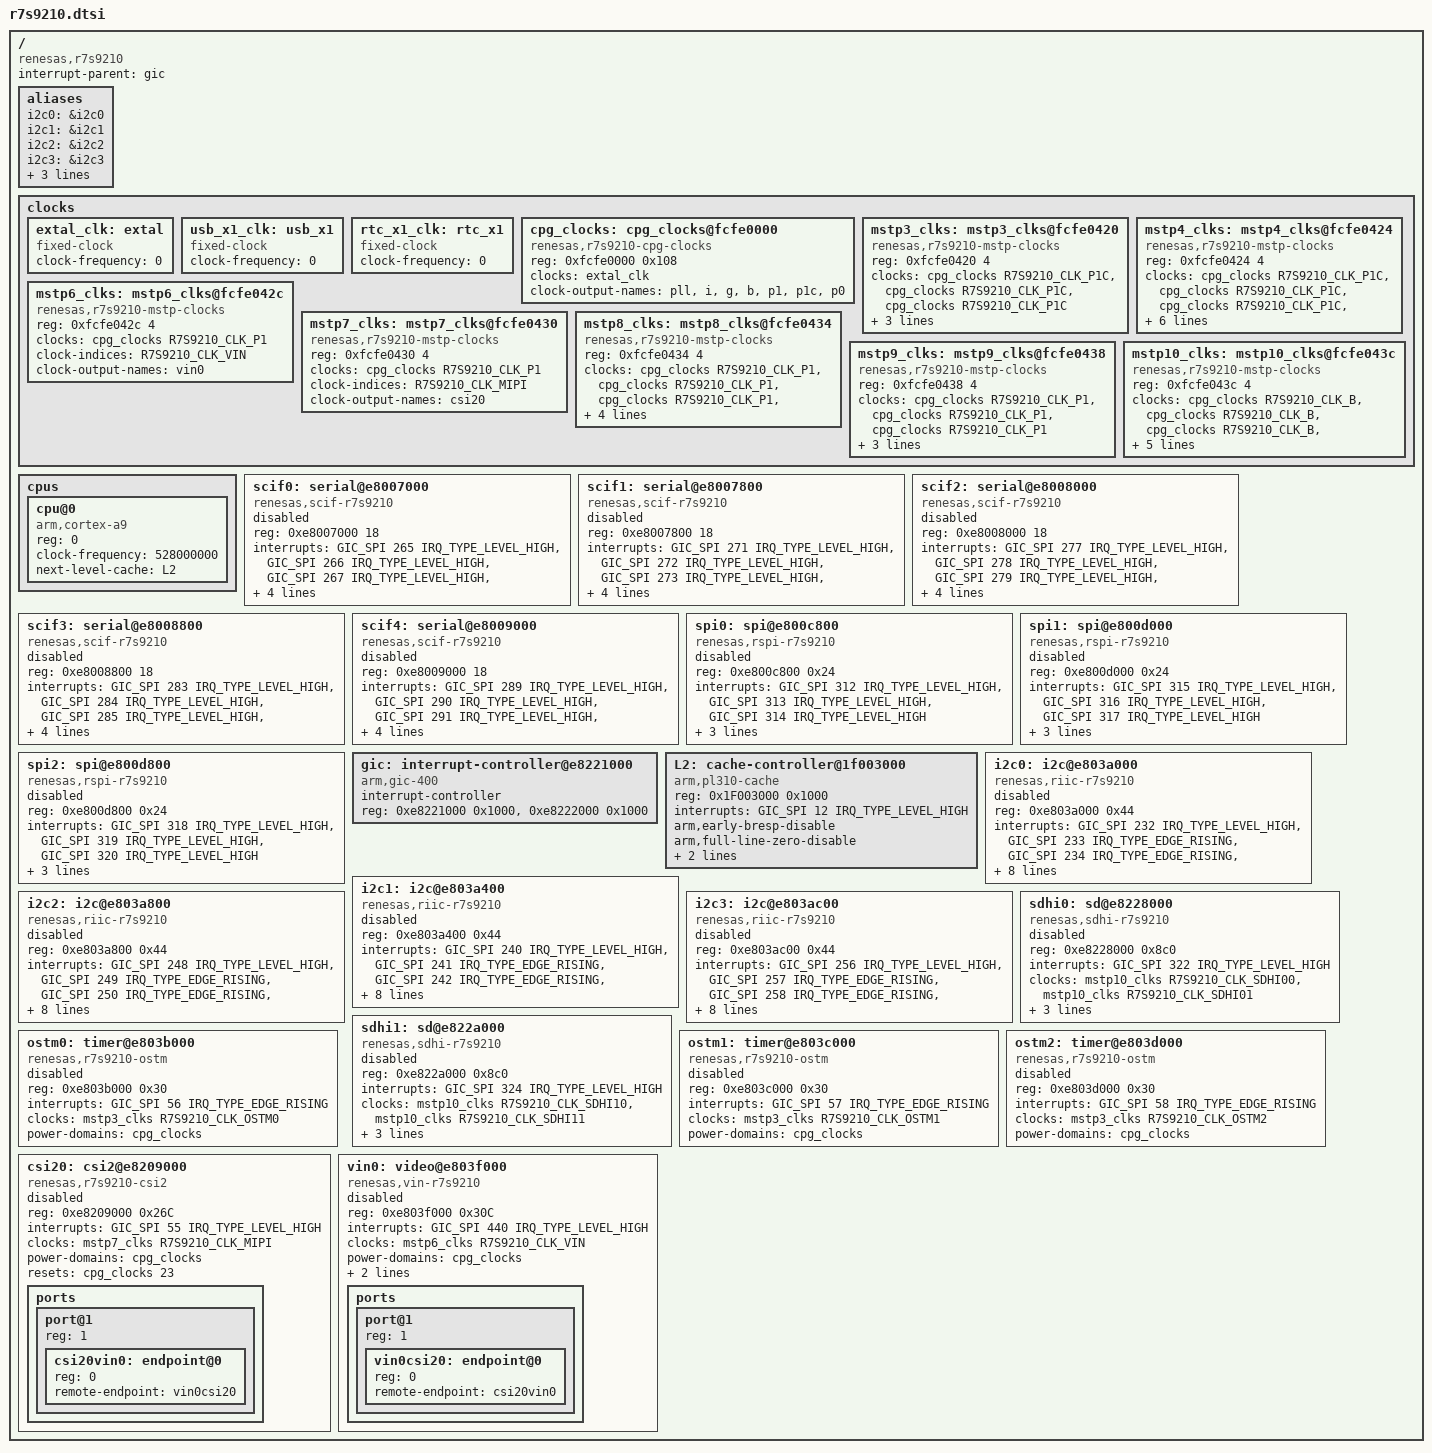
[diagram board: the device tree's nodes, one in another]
/*
 * Device Tree Source for the R7S9210 SoC
 *
 * Copyright (C) 2018 Renesas Electronics Corporation
 *
 * This file is licensed under the terms of the GNU General Public License
 * version 2.  This program is licensed "as is" without any warranty of any
 * kind, whether express or implied.
 */

#include <dt-bindings/clock/r7s9210-clock.h>
#include <dt-bindings/interrupt-controller/arm-gic.h>
#include <dt-bindings/interrupt-controller/irq.h>
#define RZA1DMA_SLAVE_PCM_MEM_SSI0 1
#define RZA1DMA_SLAVE_PCM_MEM_SRC1 2
#define RZA1DMA_SLAVE_PCM_SSI0_MEM 3
#define RZA1DMA_SLAVE_PCM_SRC0_MEM 4
#define RZA1DMA_SLAVE_PCM_MAX 5
#define RZA1DMA_SLAVE_SDHI0_TX 6
#define RZA1DMA_SLAVE_SDHI0_RX 7
#define RZA1DMA_SLAVE_SDHI1_TX 8
#define RZA1DMA_SLAVE_SDHI1_RX 9
#define RZA1DMA_SLAVE_MMCIF_TX 10
#define RZA1DMA_SLAVE_MMCIF_RX 11

/ {
	compatible = "renesas,r7s9210";
	interrupt-parent = <&gic>;
	#address-cells = <1>;
	#size-cells = <1>;

	aliases {
		i2c0 = &i2c0;
		i2c1 = &i2c1;
		i2c2 = &i2c2;
		i2c3 = &i2c3;
		spi0 = &spi0;
		spi1 = &spi1;
		spi2 = &spi2;
//		spi3 = &spibsc0;
	};

	clocks {
		ranges;
		#address-cells = <1>;
		#size-cells = <1>;

		/* External clocks */
		extal_clk: extal {
			#clock-cells = <0>;
			compatible = "fixed-clock";
			/* If clk present, value must be set by board */
			clock-frequency = <0>;
		};

		usb_x1_clk: usb_x1 {
			#clock-cells = <0>;
			compatible = "fixed-clock";
			/* If clk present, value must be set by board */
			clock-frequency = <0>;
		};

		rtc_x1_clk: rtc_x1 {
			#clock-cells = <0>;
			compatible = "fixed-clock";
			/* If clk present, value must be set by board to 32678 */
			clock-frequency = <0>;
		};

		/* CPG clocks */
		cpg_clocks: cpg_clocks@fcfe0000 {
			#clock-cells = <1>;
			compatible = "renesas,r7s9210-cpg-clocks",
				     "renesas,rz-cpg-clocks";
			reg = <0xfcfe0000 0x108>;
			clocks = <&extal_clk>;
			clock-output-names = "pll", "i", "g", "b", "p1", "p1c", "p0";
			#power-domain-cells = <0>;
			#reset-cells = <0>;
		};

		/* MSTP clocks */
//	clock-output-names = 
//	"mtu3"
//	"rtc"
//	"ether0", "ether0"
//	"usb0", "usb1"
//	"mmcif"
//	,
//	"vdc6",
//	"spibsc"
//	"spi0", "spi1", "spi2"
		mstp3_clks: mstp3_clks@fcfe0420 {
			#clock-cells = <1>;
			compatible = "renesas,r7s9210-mstp-clocks", "renesas,cpg-mstp-clocks";
			reg = <0xfcfe0420 4>;
			clocks = <&cpg_clocks R7S9210_CLK_P1C>, <&cpg_clocks R7S9210_CLK_P1C>, <&cpg_clocks R7S9210_CLK_P1C>;
			clock-indices = <R7S9210_CLK_OSTM0 R7S9210_CLK_OSTM1 R7S9210_CLK_OSTM2>;
			clock-output-names = "ostm0", "ostm1", "ostm2";
		};

		mstp4_clks: mstp4_clks@fcfe0424 {
			#clock-cells = <1>;
			compatible = "renesas,r7s9210-mstp-clocks", "renesas,cpg-mstp-clocks";
			reg = <0xfcfe0424 4>;
			clocks = <&cpg_clocks R7S9210_CLK_P1C>, <&cpg_clocks R7S9210_CLK_P1C>, <&cpg_clocks R7S9210_CLK_P1C>,
				 <&cpg_clocks R7S9210_CLK_P1C>, <&cpg_clocks R7S9210_CLK_P1C>;

			clock-indices = <
				R7S9210_CLK_SCIF0 R7S9210_CLK_SCIF1 R7S9210_CLK_SCIF2
				R7S9210_CLK_SCIF3 R7S9210_CLK_SCIF4
			>;
			clock-output-names = "scif0", "scif1", "scif2", "scif3", "scif4";
		};

/*
		mstp5_clks: mstp5_clks@fcfe0428 {
			#clock-cells = <1>;
			compatible = "renesas,r7s9210-mstp-clocks", "renesas,cpg-mstp-clocks";
			reg = <0xfcfe0428 4>;
			clocks = ;
			clock-indices = ;
			clock-output-names = ;
		};
*/

		mstp6_clks: mstp6_clks@fcfe042c {
			#clock-cells = <1>;
			compatible = "renesas,r7s9210-mstp-clocks", "renesas,cpg-mstp-clocks";
			reg = <0xfcfe042c 4>;
			clocks = <&cpg_clocks R7S9210_CLK_P1>;
			clock-indices = <R7S9210_CLK_VIN>;
			clock-output-names = "vin0";

		};


		mstp7_clks: mstp7_clks@fcfe0430 {
			#clock-cells = <1>;
			compatible = "renesas,r7s9210-mstp-clocks", "renesas,cpg-mstp-clocks";
			reg = <0xfcfe0430 4>;
			clocks = <&cpg_clocks R7S9210_CLK_P1>;
			clock-indices = <R7S9210_CLK_MIPI>;
			clock-output-names = "csi20";

		};
/*
mstp7_clks: mstp7_clks@fcfe0430 {
            #clock-cells = &lt;1&gt;;
            compatible = "renesas,r7s9210-mstp-clocks", "renesas,cpg-mstp-clocks";
            reg = &lt;0xfcfe0430 4&gt;;
            clocks = &lt;&cpg_clocks R7S9210_CLK_B&gt;;
            clock-indices = &lt;R7S9210_CLK_MIPI&gt;;
            clock-output-names = "mipi";
};
*/


		mstp8_clks: mstp8_clks@fcfe0434 {
			#clock-cells = <1>;
			compatible = "renesas,r7s9210-mstp-clocks", "renesas,cpg-mstp-clocks";
			reg = <0xfcfe0434 4>;
			clocks = <&cpg_clocks R7S9210_CLK_P1>, <&cpg_clocks R7S9210_CLK_P1>, <&cpg_clocks R7S9210_CLK_P1>,
				 <&cpg_clocks R7S9210_CLK_P1>;
			clock-indices = <R7S9210_CLK_I2C0 R7S9210_CLK_I2C1 R7S9210_CLK_I2C2 R7S9210_CLK_I2C3>;
			clock-output-names = "i2c0", "i2c1", "i2c2", "i2c3";

		};

		mstp9_clks: mstp9_clks@fcfe0438 {
			#clock-cells = <1>;
			compatible = "renesas,r7s9210-mstp-clocks", "renesas,cpg-mstp-clocks";
			reg = <0xfcfe0438 4>;
			clocks = <&cpg_clocks R7S9210_CLK_P1>, <&cpg_clocks R7S9210_CLK_P1>, <&cpg_clocks R7S9210_CLK_P1>;
			clock-indices = <R7S9210_CLK_SPI0 R7S9210_CLK_SPI1 R7S9210_CLK_SPI2>;
			clock-output-names = "spi0", "spi1", "spi2";

		};

		mstp10_clks: mstp10_clks@fcfe043c {
			#clock-cells = <1>;
			compatible = "renesas,r7s9210-mstp-clocks", "renesas,cpg-mstp-clocks";
			reg = <0xfcfe043c 4>;
			clocks = <&cpg_clocks R7S9210_CLK_B>, <&cpg_clocks R7S9210_CLK_B>, <&cpg_clocks R7S9210_CLK_B>,
				 <&cpg_clocks R7S9210_CLK_B>;
			clock-indices = <R7S9210_CLK_SDHI00 R7S9210_CLK_SDHI01 R7S9210_CLK_SDHI10 R7S9210_CLK_SDHI11>;
			clock-output-names ="sdhi00", "sdhi01", "sdhi10", "sdhi11";
		};

/*
		mstp11_clks: mstp10_clks@fcfe0440 {
			#clock-cells = <1>;
			compatible = "renesas,r7s9210-mstp-clocks", "renesas,cpg-mstp-clocks";
			reg = <0xfcfe0440 4>;
			clocks = ;
			clock-indices = ;
			clock-output-names = ;
		};
*/
	};

	cpus {
		#address-cells = <1>;
		#size-cells = <0>;

		cpu@0 {
			device_type = "cpu";
			compatible = "arm,cortex-a9";
			reg = <0>;
			clock-frequency = <528000000>;
			next-level-cache = <&L2>;
		};
	};

	scif0: serial@e8007000 {
		compatible = "renesas,scif-r7s9210", "renesas,scif";
		reg = <0xe8007000 18>;
		interrupts = <GIC_SPI 265 IRQ_TYPE_LEVEL_HIGH>,
			     <GIC_SPI 266 IRQ_TYPE_LEVEL_HIGH>,
			     <GIC_SPI 267 IRQ_TYPE_LEVEL_HIGH>,
			     <GIC_SPI 265 IRQ_TYPE_LEVEL_HIGH>,
			     <GIC_SPI 268 IRQ_TYPE_LEVEL_HIGH>;
		clocks = <&mstp4_clks R7S9210_CLK_SCIF0>;
		clock-names = "fck";
		power-domains = <&cpg_clocks>;
		status = "disabled";
	};

	scif1: serial@e8007800 {
		compatible = "renesas,scif-r7s9210", "renesas,scif";
		reg = <0xe8007800 18>;
		interrupts = <GIC_SPI 271 IRQ_TYPE_LEVEL_HIGH>,
			     <GIC_SPI 272 IRQ_TYPE_LEVEL_HIGH>,
			     <GIC_SPI 273 IRQ_TYPE_LEVEL_HIGH>,
			     <GIC_SPI 271 IRQ_TYPE_LEVEL_HIGH>,
			     <GIC_SPI 274 IRQ_TYPE_LEVEL_HIGH>;
		clocks = <&mstp4_clks R7S9210_CLK_SCIF1>;
		clock-names = "fck";
		power-domains = <&cpg_clocks>;
		status = "disabled";
	};

	scif2: serial@e8008000 {
		compatible = "renesas,scif-r7s9210", "renesas,scif";
		reg = <0xe8008000 18>;
		interrupts = <GIC_SPI 277 IRQ_TYPE_LEVEL_HIGH>,
			     <GIC_SPI 278 IRQ_TYPE_LEVEL_HIGH>,
			     <GIC_SPI 279 IRQ_TYPE_LEVEL_HIGH>,
			     <GIC_SPI 277 IRQ_TYPE_LEVEL_HIGH>,
			     <GIC_SPI 280 IRQ_TYPE_LEVEL_HIGH>;
		clocks = <&mstp4_clks R7S9210_CLK_SCIF2>;
		clock-names = "fck";
		power-domains = <&cpg_clocks>;
		status = "disabled";
	};

	scif3: serial@e8008800 {
		compatible = "renesas,scif-r7s9210", "renesas,scif";
		reg = <0xe8008800 18>;
		interrupts = <GIC_SPI 283 IRQ_TYPE_LEVEL_HIGH>,
			     <GIC_SPI 284 IRQ_TYPE_LEVEL_HIGH>,
			     <GIC_SPI 285 IRQ_TYPE_LEVEL_HIGH>,
			     <GIC_SPI 283 IRQ_TYPE_LEVEL_HIGH>,
			     <GIC_SPI 286 IRQ_TYPE_LEVEL_HIGH>;
		clocks = <&mstp4_clks R7S9210_CLK_SCIF3>;
		clock-names = "fck";
		power-domains = <&cpg_clocks>;
		status = "disabled";
	};

	scif4: serial@e8009000 {
		compatible = "renesas,scif-r7s9210", "renesas,scif";
		reg = <0xe8009000 18>;
		interrupts = <GIC_SPI 289 IRQ_TYPE_LEVEL_HIGH>,
			     <GIC_SPI 290 IRQ_TYPE_LEVEL_HIGH>,
			     <GIC_SPI 291 IRQ_TYPE_LEVEL_HIGH>,
			     <GIC_SPI 289 IRQ_TYPE_LEVEL_HIGH>,
			     <GIC_SPI 292 IRQ_TYPE_LEVEL_HIGH>;
		clocks = <&mstp4_clks R7S9210_CLK_SCIF4>;
		clock-names = "fck";
		power-domains = <&cpg_clocks>;
		status = "disabled";
	};


	spi0: spi@e800c800 {
		compatible = "renesas,rspi-r7s9210", "renesas,rspi-rz";
		reg = <0xe800c800 0x24>;
		interrupts = <GIC_SPI 312 IRQ_TYPE_LEVEL_HIGH>,
			     <GIC_SPI 313 IRQ_TYPE_LEVEL_HIGH>,
			     <GIC_SPI 314 IRQ_TYPE_LEVEL_HIGH>;
		interrupt-names = "error", "rx", "tx";
		clocks = <&mstp9_clks R7S9210_CLK_SPI0>;
		power-domains = <&cpg_clocks>;
		num-cs = <1>;
		#address-cells = <1>;
		#size-cells = <0>;
		status = "disabled";
	};

	spi1: spi@e800d000 {
		compatible = "renesas,rspi-r7s9210", "renesas,rspi-rz";
		reg = <0xe800d000 0x24>;
		interrupts = <GIC_SPI 315 IRQ_TYPE_LEVEL_HIGH>,
			     <GIC_SPI 316 IRQ_TYPE_LEVEL_HIGH>,
			     <GIC_SPI 317 IRQ_TYPE_LEVEL_HIGH>;
		interrupt-names = "error", "rx", "tx";
		clocks = <&mstp9_clks R7S9210_CLK_SPI1>;
		power-domains = <&cpg_clocks>;
		num-cs = <1>;
		#address-cells = <1>;
		#size-cells = <0>;
		status = "disabled";
	};

	spi2: spi@e800d800 {
		compatible = "renesas,rspi-r7s9210", "renesas,rspi-rz";
		reg = <0xe800d800 0x24>;
		interrupts = <GIC_SPI 318 IRQ_TYPE_LEVEL_HIGH>,
			     <GIC_SPI 319 IRQ_TYPE_LEVEL_HIGH>,
			     <GIC_SPI 320 IRQ_TYPE_LEVEL_HIGH>;
		interrupt-names = "error", "rx", "tx";
		clocks = <&mstp9_clks R7S9210_CLK_SPI2>;
		power-domains = <&cpg_clocks>;
		num-cs = <1>;
		#address-cells = <1>;
		#size-cells = <0>;
		status = "disabled";
	};

	gic: interrupt-controller@e8221000 {
		compatible = "arm,gic-400";
		#interrupt-cells = <3>;
		#address-cells = <0>;
		interrupt-controller;
		reg = <0xe8221000 0x1000>,
			<0xe8222000 0x1000>;
	};

	L2: cache-controller@1f003000 {
		compatible = "arm,pl310-cache";
		reg = <0x1F003000 0x1000>;
		interrupts = <GIC_SPI 12 IRQ_TYPE_LEVEL_HIGH>;
		arm,early-bresp-disable;
		arm,full-line-zero-disable;
		cache-unified;
		cache-level = <2>;
	};
/*
	wdt: watchdog@fcfe0000 {
		compatible = "renesas,r7s9210-wdt", "renesas,rza-wdt";
		reg = <0xfcfe0000 0x6>;
		interrupts = <GIC_SPI 106 IRQ_TYPE_EDGE_RISING>;
		clocks = <&cpg_clocks R7S9210_CLK_P0>;
	};
*/

	i2c0: i2c@e803a000 {
		#address-cells = <1>;
		#size-cells = <0>;
		compatible = "renesas,riic-r7s9210", "renesas,riic-rz";
		reg = <0xe803a000 0x44>;
		interrupts = <GIC_SPI 232 IRQ_TYPE_LEVEL_HIGH>,
			     <GIC_SPI 233 IRQ_TYPE_EDGE_RISING>,
			     <GIC_SPI 234 IRQ_TYPE_EDGE_RISING>,
			     <GIC_SPI 235 IRQ_TYPE_LEVEL_HIGH>,
			     <GIC_SPI 236 IRQ_TYPE_LEVEL_HIGH>,
			     <GIC_SPI 237 IRQ_TYPE_LEVEL_HIGH>,
			     <GIC_SPI 238 IRQ_TYPE_LEVEL_HIGH>,
			     <GIC_SPI 239 IRQ_TYPE_LEVEL_HIGH>;
		clocks = <&mstp8_clks R7S9210_CLK_I2C0>;
		clock-frequency = <100000>;
		power-domains = <&cpg_clocks>;
		status = "disabled";
	};

	i2c1: i2c@e803a400 {
		#address-cells = <1>;
		#size-cells = <0>;
		compatible = "renesas,riic-r7s9210", "renesas,riic-rz";
		reg = <0xe803a400 0x44>;
		interrupts = <GIC_SPI 240 IRQ_TYPE_LEVEL_HIGH>,
			     <GIC_SPI 241 IRQ_TYPE_EDGE_RISING>,
			     <GIC_SPI 242 IRQ_TYPE_EDGE_RISING>,
			     <GIC_SPI 243 IRQ_TYPE_LEVEL_HIGH>,
			     <GIC_SPI 244 IRQ_TYPE_LEVEL_HIGH>,
			     <GIC_SPI 245 IRQ_TYPE_LEVEL_HIGH>,
			     <GIC_SPI 246 IRQ_TYPE_LEVEL_HIGH>,
			     <GIC_SPI 247 IRQ_TYPE_LEVEL_HIGH>;
		clocks = <&mstp8_clks R7S9210_CLK_I2C1>;
		clock-frequency = <100000>;
		power-domains = <&cpg_clocks>;
		status = "disabled";
	};

	i2c2: i2c@e803a800 {
		#address-cells = <1>;
		#size-cells = <0>;
		compatible = "renesas,riic-r7s9210", "renesas,riic-rz";
		reg = <0xe803a800 0x44>;
		interrupts = <GIC_SPI 248 IRQ_TYPE_LEVEL_HIGH>,
			     <GIC_SPI 249 IRQ_TYPE_EDGE_RISING>,
			     <GIC_SPI 250 IRQ_TYPE_EDGE_RISING>,
			     <GIC_SPI 251 IRQ_TYPE_LEVEL_HIGH>,
			     <GIC_SPI 252 IRQ_TYPE_LEVEL_HIGH>,
			     <GIC_SPI 253 IRQ_TYPE_LEVEL_HIGH>,
			     <GIC_SPI 254 IRQ_TYPE_LEVEL_HIGH>,
			     <GIC_SPI 255 IRQ_TYPE_LEVEL_HIGH>;
		clocks = <&mstp8_clks R7S9210_CLK_I2C2>;
		clock-frequency = <100000>;
		power-domains = <&cpg_clocks>;
		status = "disabled";
	};

	i2c3: i2c@e803ac00 {
		#address-cells = <1>;
		#size-cells = <0>;
		compatible = "renesas,riic-r7s9210", "renesas,riic-rz";
		reg = <0xe803ac00 0x44>;
		interrupts = <GIC_SPI 256 IRQ_TYPE_LEVEL_HIGH>,
			     <GIC_SPI 257 IRQ_TYPE_EDGE_RISING>,
			     <GIC_SPI 258 IRQ_TYPE_EDGE_RISING>,
			     <GIC_SPI 259 IRQ_TYPE_LEVEL_HIGH>,
			     <GIC_SPI 260 IRQ_TYPE_LEVEL_HIGH>,
			     <GIC_SPI 261 IRQ_TYPE_LEVEL_HIGH>,
			     <GIC_SPI 262 IRQ_TYPE_LEVEL_HIGH>,
			     <GIC_SPI 263 IRQ_TYPE_LEVEL_HIGH>;
		clocks = <&mstp8_clks R7S9210_CLK_I2C3>;
		clock-frequency = <100000>;
		power-domains = <&cpg_clocks>;
		status = "disabled";
	};

/*
	mtu3: timer@fcff0000 {
		compatible = "renesas,mtu3-r7s9210", "renesas,mtu3";
		reg = <0xfcff0000 0x400>;
		interrupts = <GIC_SPI 107 IRQ_TYPE_LEVEL_HIGH>;
		interrupt-names = "tgi0a";
		clocks = <&mstp3_clks R7S9210_CLK_MTU2>;
		clock-names = "fck";
		power-domains = <&cpg_clocks>;
		status = "disabled";
	};
*/
/*
	dma0: dma-controller@e8200000 {
		compatible = "renesas,rza-dma";
		reg = 	<0xe8200000 0x1000>,
			<0xfcfe1000 0x1000>;

		interrupts = 	<GIC_SPI 9 IRQ_TYPE_LEVEL_HIGH>,
				<GIC_SPI 10 IRQ_TYPE_LEVEL_HIGH>,
				<GIC_SPI 11 IRQ_TYPE_LEVEL_HIGH>,
				<GIC_SPI 12 IRQ_TYPE_LEVEL_HIGH>,
				<GIC_SPI 13 IRQ_TYPE_LEVEL_HIGH>,
				<GIC_SPI 14 IRQ_TYPE_LEVEL_HIGH>,
				<GIC_SPI 15 IRQ_TYPE_LEVEL_HIGH>,
				<GIC_SPI 16 IRQ_TYPE_LEVEL_HIGH>,
				<GIC_SPI 17 IRQ_TYPE_LEVEL_HIGH>,
				<GIC_SPI 18 IRQ_TYPE_LEVEL_HIGH>,
				<GIC_SPI 19 IRQ_TYPE_LEVEL_HIGH>,
				<GIC_SPI 20 IRQ_TYPE_LEVEL_HIGH>,
				<GIC_SPI 21 IRQ_TYPE_LEVEL_HIGH>,
				<GIC_SPI 22 IRQ_TYPE_LEVEL_HIGH>,
				<GIC_SPI 23 IRQ_TYPE_LEVEL_HIGH>,
				<GIC_SPI 24 IRQ_TYPE_LEVEL_HIGH>,
				<GIC_SPI 25 IRQ_TYPE_LEVEL_HIGH>;
		interrupt-names = "ch0", "ch1", "ch2", "ch3",
				  "ch4", "ch5", "ch6", "ch7",
				  "ch8", "ch9", "ch10", "ch11",
				  "ch12", "ch13", "ch14", "ch15",
				  "error";
		dma-channels = <16>;
		#dma-cells = <1>;
	};
*/
/*
	ether: ethernet@e8203000 {
		compatible = "renesas,ether-r7s9210";
		reg = <0xe8203000 0x800>,
		      <0xe8204800 0x200>;
		interrupts = <GIC_SPI 327 IRQ_TYPE_LEVEL_HIGH>;
		clocks = <&mstp7_clks R7S9210_CLK_ETHER>;
		power-domains = <&cpg_clocks>;
		phy-mode = "mii";
		#address-cells = <1>;
		#size-cells = <0>;
		status = "disabled";
	};
*/
/*
	mmcif: mmc@e804c800 {
		compatible = "renesas,mmcif-r7s9210", "renesas,sh-mmcif";
		reg = <0xe804c800 0x80>;
		interrupts = <GIC_SPI 268 IRQ_TYPE_LEVEL_HIGH
			      GIC_SPI 269 IRQ_TYPE_LEVEL_HIGH
			      GIC_SPI 267 IRQ_TYPE_LEVEL_HIGH>;
		clocks = <&mstp8_clks R7S9210_CLK_MMCIF>;
		power-domains = <&cpg_clocks>;
		reg-io-width = <4>;
		bus-width = <8>;
		status = "disabled";
	};
*/

	sdhi0: sd@e8228000 {
		compatible = "renesas,sdhi-r7s9210";
		reg = <0xe8228000 0x8c0>;
		interrupts = <GIC_SPI 322 IRQ_TYPE_LEVEL_HIGH>;
		clocks = <&mstp10_clks R7S9210_CLK_SDHI00>,
				 <&mstp10_clks R7S9210_CLK_SDHI01>;
		clock-names = "core", "cd";
		power-domains = <&cpg_clocks>;
		cap-sd-highspeed;
		cap-sdio-irq;
		status = "disabled";
	};

	sdhi1: sd@e822a000 {
		compatible = "renesas,sdhi-r7s9210";
		reg = <0xe822a000 0x8c0>;
		interrupts = <GIC_SPI 324 IRQ_TYPE_LEVEL_HIGH>;
		clocks = <&mstp10_clks R7S9210_CLK_SDHI10>,
				 <&mstp10_clks R7S9210_CLK_SDHI11>;
		clock-names = "core", "cd";
		power-domains = <&cpg_clocks>;
		cap-sd-highspeed;
		cap-sdio-irq;
		status = "disabled";
	};

	ostm0: timer@e803b000 {
		compatible = "renesas,r7s9210-ostm", "renesas,ostm";
		reg = <0xe803b000 0x30>;
		interrupts = <GIC_SPI 56 IRQ_TYPE_EDGE_RISING>;
		clocks = <&mstp3_clks R7S9210_CLK_OSTM0>;
		power-domains = <&cpg_clocks>;
		status = "disabled";
	};

	ostm1: timer@e803c000 {
		compatible = "renesas,r7s9210-ostm", "renesas,ostm";
		reg = <0xe803c000 0x30>;
		interrupts = <GIC_SPI 57 IRQ_TYPE_EDGE_RISING>;
		clocks = <&mstp3_clks R7S9210_CLK_OSTM1>;
		power-domains = <&cpg_clocks>;
		status = "disabled";
	};

	ostm2: timer@e803d000 {
		compatible = "renesas,r7s9210-ostm", "renesas,ostm";
		reg = <0xe803d000 0x30>;
		interrupts = <GIC_SPI 58 IRQ_TYPE_EDGE_RISING>;
		clocks = <&mstp3_clks R7S9210_CLK_OSTM2>;
		power-domains = <&cpg_clocks>;
		status = "disabled";
	};

	csi20: csi2@e8209000 {
		compatible = "renesas,r7s9210-csi2", "renesas,r8a77990-csi2", "renesas,rcar-gen3-csi2";
		reg = <0xe8209000 0x26C>;
		interrupts = <GIC_SPI 55 IRQ_TYPE_LEVEL_HIGH>;
		clocks = <&mstp7_clks R7S9210_CLK_MIPI>;
		power-domains = <&cpg_clocks>;
		resets = <&cpg_clocks 23>;
		status = "disabled";

		ports {
			#address-cells = <1>;
			#size-cells = <0>;

			port@1 {
				#address-cells = <1>;
				#size-cells = <0>;

				reg = <1>;

				csi20vin0: endpoint@0 {
					reg = <0>;
					remote-endpoint = <&vin0csi20>;
				};
			};
		};
	};

/*
csi20: csi2@e8209000 {
        compatible = "renesas,r7s9210-csi2", "renesas,r8a77990-csi2", "renesas,rcar-gen3-csi2";
        reg = &lt;0 0xe8209000 0 0x10000&gt;;
        interrupts = &lt;GIC_SPI 55 IRQ_TYPE_LEVEL_HIGH&gt;;
        clocks = &lt;&mstp7_clks R7S9210_CLK_MIPI&gt;;
        //power-domains = &lt;&sysc R8A77990_PD_ALWAYS_ON&gt;;
        resets = &lt;&cpg_clocks 23&gt;;
        status = "disabled";
ports {
            #address-cells = &lt;1&gt;;
            #size-cells = &lt;0&gt;;
port@1 {
                #address-cells = &lt;1&gt;;
                #size-cells = &lt;0&gt;;
		reg = &lt;1&gt;;

}*/	
	vin0: video@e803f000 {
		compatible = "renesas,vin-r7s9210";
		reg = <0xe803f000 0x30C>;
		interrupts = <GIC_SPI 440 IRQ_TYPE_LEVEL_HIGH>;
		clocks = <&mstp6_clks R7S9210_CLK_VIN>;
		power-domains = <&cpg_clocks>;
		resets = <&cpg_clocks 25>;
		renesas,id = <0>;
		status = "disabled";

		ports {
			#address-cells = <1>;
			#size-cells = <0>;

			port@1 {
				#address-cells = <1>;
				#size-cells = <0>;

				reg = <1>;

				vin0csi20: endpoint@0 {
					reg = <0>;
					remote-endpoint= <&csi20vin0>;
				};
			};
		};
	};	
/*
	rtc: rtc@fcff1000 {
		compatible = "renesas,r7s9210-rtc", "renesas,sh-rtc";
		reg = <0xfcff1000 0x2e>;
		interrupts = <GIC_SPI 276 IRQ_TYPE_EDGE_RISING
			      GIC_SPI 277 IRQ_TYPE_EDGE_RISING
			      GIC_SPI 278 IRQ_TYPE_EDGE_RISING>;
		interrupt-names = "alarm", "period", "carry";
		clocks = <&mstp6_clks R7S9210_CLK_RTC>, <&rtc_x1_clk>,
			 <&extal_clk>;
		clock-names = "fck", "rtc_x1", "extal";
		power-domains = <&cpg_clocks>;
		status = "disabled";
	};
*/
/*
	usbhs0: usb@e8010000 {
		compatible = "renesas,usbhs-r7s9210", "renesas,rza1-usbhs";
		reg = <0xe8010000 0x1a0>;
		interrupts = <GIC_SPI 41 IRQ_TYPE_LEVEL_HIGH>;
		clocks = <&mstp7_clks R7S9210_CLK_USB0>;
		renesas,buswait = <4>;
		power-domains = <&cpg_clocks>;
		status = "disabled";
	};

	usbhs1: usb@e8207000 {
		compatible = "renesas,usbhs-r7s9210", "renesas,rza1-usbhs";
		reg = <0xe8207000 0x1a0>;
		interrupts = <GIC_SPI 42 IRQ_TYPE_LEVEL_HIGH>;
		clocks = <&mstp7_clks R7S9210_CLK_USB1>;
		renesas,buswait = <4>;
		power-domains = <&cpg_clocks>;
		status = "disabled";
	};
*/
	/**** non-upstream drivers ****/
/*
	usbhost0: usbhost@e8010000 {
		compatible = "renesas,r7s9210-r8a66597-hdc", "renesas,r8a66597-hdc";
		reg = <0xe8010000 0x1A0>;
		interrupts = <GIC_SPI (73-32) IRQ_TYPE_LEVEL_HIGH>;
		clocks = <&mstp7_clks R7S9210_CLK_USB0>;
		power-domains = <&cpg_clocks>;
		status = "disabled";
	};

	usbhost1: usbhost@e8207000 {
		compatible = "renesas,r7s9210-r8a66597-hdc", "renesas,r8a66597-hdc";
		reg = <0xe8207000 0x1A0>;
		interrupts = <GIC_SPI (74-32) IRQ_TYPE_LEVEL_HIGH>;
		clocks = <&mstp7_clks R7S9210_CLK_USB1>;
		power-domains = <&cpg_clocks>;
		status = "disabled";
	};
*/
#if 0
	vdc6: display@fcff7400 {
		compatible = "renesas,r7s9210-vdc6fb";
		reg = <0xfcff7400 0x00000700>,
		      <0xfcff6000 0x00001000>,
		      <0xfcff7a30 0x00000030>;
		reg-names = "reg", "clut", "lvds";
		/* interrupts = (are not used with this driver) */
		channel = <0>;
		clocks = <&mstp9_clks R7S9210_CLK_VDC6>;
		status = "disabled";
	};
#endif
/*
	spibsc: spi@3fefa000 {
		compatible = "renesas,r7s9210-spibsc";
		reg = <0x3fefa000 0x100>;
		clocks = <&mstp9_clks R7S9210_CLK_SPIBSC>;
		#address-cells = <1>;
		#size-cells = <0>;
		status = "disabled";
	};
*/

};
